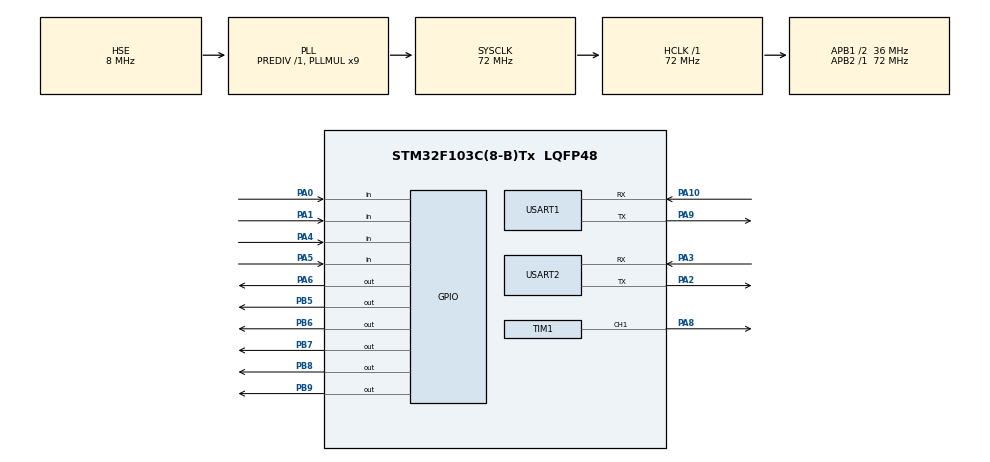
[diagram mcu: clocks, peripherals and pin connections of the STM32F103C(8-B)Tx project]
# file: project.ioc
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Dma.Request0=USART2_RX
Dma.USART2_RX.0.Direction=DMA_PERIPH_TO_MEMORY
Dma.USART2_RX.0.Instance=DMA1_Channel6
Dma.USART2_RX.0.MemDataAlignment=DMA_MDATAALIGN_BYTE
Dma.USART2_RX.0.MemInc=DMA_MINC_ENABLE
Dma.USART2_RX.0.Mode=DMA_CIRCULAR
Dma.USART2_RX.0.PeriphDataAlignment=DMA_PDATAALIGN_BYTE
Dma.USART2_RX.0.PeriphInc=DMA_PINC_DISABLE
Dma.USART2_RX.0.Priority=DMA_PRIORITY_LOW
Mcu.Family=STM32F1
Mcu.Name=STM32F103C(8-B)Tx
Mcu.Package=LQFP48
NVIC.DMA1_Channel6_IRQn=true\:5\:0\:false\:false\:true\:false\:true\:true
NVIC.PriorityGroup=NVIC_PRIORITYGROUP_4
NVIC.TIM4_IRQn=true\:15\:0\:false\:false\:true\:false\:true\:true
NVIC.TimeBase=TIM4_IRQn
NVIC.TimeBaseIP=TIM4
NVIC.USART1_IRQn=true\:6\:0\:false\:false\:true\:false\:true\:true
NVIC.USART2_IRQn=true\:5\:0\:false\:false\:true\:false\:true\:true
PA0-WKUP.GPIO_PuPd=GPIO_PULLUP
PA0-WKUP.Signal=GPIO_Input
PA1.GPIO_PuPd=GPIO_PULLUP
PA1.Signal=GPIO_Input
PA10.GPIO_PuPd=GPIO_PULLUP
PA10.Mode=Asynchronous
PA10.Signal=USART1_RX
PA13.Mode=Serial_Wire
PA13.Signal=SYS_JTMS-SWDIO
PA14.Mode=Serial_Wire
PA14.Signal=SYS_JTCK-SWCLK
PA2.GPIO_Speed=GPIO_SPEED_FREQ_HIGH
PA2.Mode=Asynchronous
PA2.Signal=USART2_TX
PA3.GPIO_PuPd=GPIO_NOPULL
PA3.Mode=Asynchronous
PA3.Signal=USART2_RX
PA4.GPIO_PuPd=GPIO_PULLUP
PA4.Signal=GPIO_Input
PA5.GPIO_PuPd=GPIO_PULLUP
PA5.Signal=GPIO_Input
PA6.GPIO_ModeDefaultOutputPP=GPIO_MODE_OUTPUT_PP
PA6.GPIO_PuPd=GPIO_NOPULL
PA6.PinState=GPIO_PIN_SET
PA6.Signal=GPIO_Output
PA8.GPIO_Speed=GPIO_SPEED_FREQ_LOW
PA8.Signal=S_TIM1_CH1
PA9.GPIO_Speed=GPIO_SPEED_FREQ_HIGH
PA9.Mode=Asynchronous
PA9.Signal=USART1_TX
PB5.PinState=GPIO_PIN_SET
PB5.Signal=GPIO_Output
PB6.GPIO_ModeDefaultOutputPP=GPIO_MODE_OUTPUT_OD
PB6.GPIO_PuPd=GPIO_NOPULL
PB6.GPIO_Speed=GPIO_SPEED_FREQ_HIGH
PB6.PinState=GPIO_PIN_SET
PB6.Signal=GPIO_Output
PB7.GPIO_ModeDefaultOutputPP=GPIO_MODE_OUTPUT_OD
PB7.GPIO_PuPd=GPIO_NOPULL
PB7.GPIO_Speed=GPIO_SPEED_FREQ_HIGH
PB7.PinState=GPIO_PIN_SET
PB7.Signal=GPIO_Output
PB8.GPIO_ModeDefaultOutputPP=GPIO_MODE_OUTPUT_OD
PB8.GPIO_PuPd=GPIO_NOPULL
PB8.GPIO_Speed=GPIO_SPEED_FREQ_HIGH
PB8.PinState=GPIO_PIN_SET
PB8.Signal=GPIO_Output
PB9.GPIO_ModeDefaultOutputPP=GPIO_MODE_OUTPUT_OD
PB9.GPIO_PuPd=GPIO_NOPULL
PB9.GPIO_Speed=GPIO_SPEED_FREQ_HIGH
PB9.PinState=GPIO_PIN_SET
PB9.Signal=GPIO_Output
PD0-OSC_IN.Mode=HSE-External-Oscillator
PD0-OSC_IN.Signal=RCC_OSC_IN
PD1-OSC_OUT.Mode=HSE-External-Oscillator
PD1-OSC_OUT.Signal=RCC_OSC_OUT
ProjectManager.HeapSize=0x200
ProjectManager.StackSize=0x400
ProjectManager.TargetToolchain=MDK-ARM V5.32
RCC.AHBFreq_Value=72000000
RCC.APB1CLKDivider=RCC_HCLK_DIV2
RCC.APB1Freq_Value=36000000
RCC.APB1TimFreq_Value=72000000
RCC.APB2Freq_Value=72000000
RCC.APB2TimFreq_Value=72000000
RCC.HCLKFreq_Value=72000000
RCC.PLLMUL=RCC_PLL_MUL9
RCC.PLLSourceVirtual=RCC_PLLSOURCE_HSE
RCC.SYSCLKFreq_VALUE=72000000
RCC.SYSCLKSource=RCC_SYSCLKSOURCE_PLLCLK
RCC.USBFreq_Value=72000000
SH.S_TIM1_CH1.0=TIM1_CH1,PWM Generation1 CH1
TIM1.AutoReloadPreload=TIM_AUTORELOAD_PRELOAD_ENABLE
TIM1.Channel-PWM\ Generation1\ CH1=TIM_CHANNEL_1
TIM1.Period=999
TIM1.Prescaler=71
TIM2.Prescaler=71
USART1.VirtualMode=VM_ASYNC
USART2.VirtualMode=VM_ASYNC
VP_SYS_VS_tim4.Mode=TIM4
VP_TIM1_VS_ClockSourceINT.Mode=Internal
VP_TIM2_VS_ClockSourceINT.Mode=Internal
board=custom

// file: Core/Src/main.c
/* USER CODE BEGIN Header */
/**
  ******************************************************************************
  * @file           : main.c
  * @brief          : Main program body
  ******************************************************************************
  * @attention
  *
  * Copyright (c) 2026 STMicroelectronics.
  * All rights reserved.
  *
  * This software is licensed under terms that can be found in the LICENSE file
  * in the root directory of this software component.
  * If no LICENSE file comes with this software, it is provided AS-IS.
  *
  ******************************************************************************
  */
/* USER CODE END Header */
#include "main.h"
#include "dma.h"
#include "tim.h"
#include "usart.h"
#include "gpio.h"

/* USER CODE BEGIN Includes */

#include "app_main.h"     /* 应用层总入口 */

/* USER CODE END Includes */

void SystemClock_Config(void);

int main(void)
{

  /* MCU Configuration--------------------------------------------------------*/

  /* Reset of all peripherals, Initializes the Flash interface and the Systick. */
  HAL_Init();

  /* Configure the system clock */
  SystemClock_Config();

  /* Initialize all configured peripherals */
  MX_GPIO_Init();
  MX_DMA_Init();
  MX_USART1_UART_Init();
  MX_USART2_UART_Init();
  MX_TIM2_Init();
  MX_TIM1_Init();
  /* USER CODE BEGIN 2 */

  App_Init();              //应用层总入口: 建数据通道 + 建任务

  vTaskStartScheduler();   // 启动FreeRTOS 调度器

  /* USER CODE END 2 */

  /* Infinite loop */
  while (1)
  {

  }
}

void SystemClock_Config(void)
{
  RCC_OscInitTypeDef RCC_OscInitStruct = {0};
  RCC_ClkInitTypeDef RCC_ClkInitStruct = {0};

  /** Initializes the RCC Oscillators according to the specified parameters
  * in the RCC_OscInitTypeDef structure.
  */
  RCC_OscInitStruct.OscillatorType = RCC_OSCILLATORTYPE_HSE;
  RCC_OscInitStruct.HSEState = RCC_HSE_ON;
  RCC_OscInitStruct.HSEPredivValue = RCC_HSE_PREDIV_DIV1;
  RCC_OscInitStruct.HSIState = RCC_HSI_ON;
  RCC_OscInitStruct.PLL.PLLState = RCC_PLL_ON;
  RCC_OscInitStruct.PLL.PLLSource = RCC_PLLSOURCE_HSE;
  RCC_OscInitStruct.PLL.PLLMUL = RCC_PLL_MUL9;
  if (HAL_RCC_OscConfig(&RCC_OscInitStruct) != HAL_OK)
  {
    Error_Handler();
  }

  /** Initializes the CPU, AHB and APB buses clocks
  */
  RCC_ClkInitStruct.ClockType = RCC_CLOCKTYPE_HCLK|RCC_CLOCKTYPE_SYSCLK
                              |RCC_CLOCKTYPE_PCLK1|RCC_CLOCKTYPE_PCLK2;
  RCC_ClkInitStruct.SYSCLKSource = RCC_SYSCLKSOURCE_PLLCLK;
  RCC_ClkInitStruct.AHBCLKDivider = RCC_SYSCLK_DIV1;
  RCC_ClkInitStruct.APB1CLKDivider = RCC_HCLK_DIV2;
  RCC_ClkInitStruct.APB2CLKDivider = RCC_HCLK_DIV1;

  if (HAL_RCC_ClockConfig(&RCC_ClkInitStruct, FLASH_LATENCY_2) != HAL_OK)
  {
    Error_Handler();
  }
}

/* USER CODE BEGIN 4 */

/* USART1 专职天问语音模块 (见 BSP/ASR/asr.h), 本工程不再有 printf 重定向:
 * 串口助手那一路已撤掉, 各任务里的 printf 也全部清掉了。ESP8266 / ASR 拼
 * 报文用的 snprintf 在各自模块内部完成, 不经过 fputc。 */
/* USER CODE END 4 */

void HAL_TIM_PeriodElapsedCallback(TIM_HandleTypeDef *htim)
{
  if (htim->Instance == TIM4)
  {
    HAL_IncTick();
  }
}

void Error_Handler(void)
{
  __disable_irq();
  while (1)
  {
  }
}
